# MEC1727N_B0_SZ register map
Vendor: Microchip Technology; Series: MEC172x; File version: 0
CPU: CM4 r1p0, little endian, MPU, FPU, 3 interrupt priority bits, 172 interrupts
Registers are 32-bit, read-write, reset 0x0 unless marked. A register's access mark holds for its fields unless they carry their own. Offsets are from the block's base; [hi:lo] are bit positions; {n}, {i} and the like mark numbered series; 'fields as' and 'values as' point back to an identical list.

## ESPI_IO — The ESPI is used by the system host to configure the chip and communicate with the logical devices implemented in the design.
Base 0x400F3400
0x00 IND 8-bit — The INDEX register, which is part of the Configuration Port, is used as a pointer to a Configuration Register Address.
0x01 DAT_REG 8-bit — The DATA register, which is part of the Configuration Port, is used to read or write data to the register currently being selected by the INDEX Register.
0x100 PC_LC_ADDR_LSW ro — Peripheral Channel Last Cycle Register (DWord 0)
  [31:0] LADR — This field records bits[31:0] of the 64 bit address of the most recent eSPI transaction.
0x104 PC_LC_ADDR_MSW ro — Peripheral Channel Last Cycle Register (DWord 1)
  [31:0] MADR — This field records bits[63:32] of the 64 bit address of the most recent eSPI transaction.
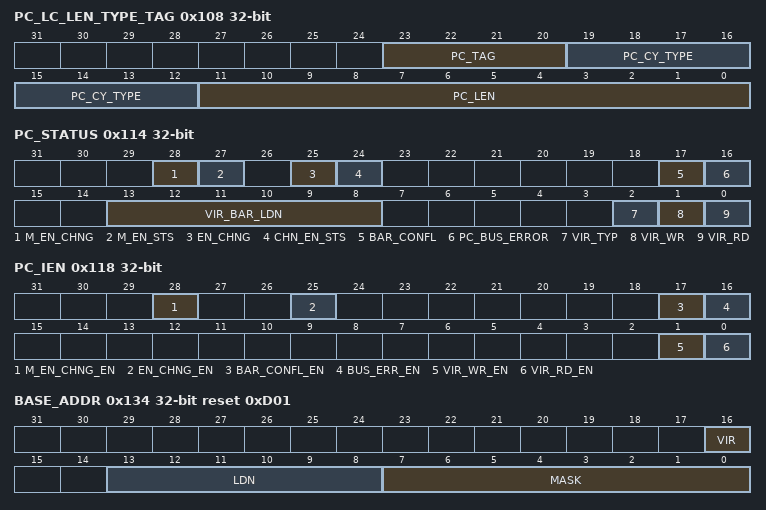
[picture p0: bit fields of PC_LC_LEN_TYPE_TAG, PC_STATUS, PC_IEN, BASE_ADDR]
0x108 PC_LC_LEN_TYPE_TAG ro — Peripheral Channel Last Cycle Register (DWord 2)
  [23:20] PC_TAG — This field records the tag of the most recent eSPI transaction.
  [19:12] PC_CY_TYPE — This field records the cycle type of the most recent eSPI transaction.
  [11:0] PC_LEN — This field records the length of the most recent eSPI transaction.
0x10C PC_ERR_ADDR_LSW ro — Peripheral Channel Error Address Register (DWord 0)
  [31:0] LSDW — This field records bits[31:0] of the 64 bit address of the most recent eSPI transaction that incurred an error.
0x110 PC_ERR_ADDR_MSW ro — Peripheral Channel Error Address Register (DWord 1)
  [31:0] MSDW — This field records bits[63:32] of the 64 bit address of the most recent eSPI transaction that incurred an error.
0x114 PC_STATUS — Peripheral Channel Status Register
  [28] M_EN_CHNG — This bit is set to '1' whenever the field PC_MASTERING_ENABLE_STATUS in this register changes. Once set, it remains set until cleared by being written with a 1 (R/WC)
  [27] M_EN_STS — This bit is 1 if three bits in the Peripheral Channel Capabilities and Configurations register, Peripheral Channel Mastering Enable, Peripheral Channel Ready and Peripheral Channel Enable, are all 1, and 0 otherwise.
  [25] EN_CHNG — This bit is set to '1' whenever the field PC_CHANNEL_ENABLE_STATUS in this register changes. Once set, it remains set until cleared by being written with a 1. (R/WC)
  [24] CHN_EN_STS — This bit reflects the Host writable configuration field.
  [17] BAR_CONFL — This bit is set to '1' whenever a BAR conflict occurs on an eSPI address. A BAR conflict occurs when more than one BAR matches the address of an eSPI transaction. Once set, it remains set until cleared by being written with a 1. (R/WC)
  [16] PC_BUS_ERROR — This bit is set to '1' whenever an eSPI access causes an internal bus error. Once set, it remains set until cleared by being written with a 1. (R/WC)
  [13:8] VIR_BAR_LDN — This field returns the Logical Device Number of the device targeted by the most recent virtual transaction.
  [2] VIR_TYP — This bit returns the type of Virtualized eSPI transaction that is 1=Peripheral Channel Memory Address access 0=Peripheral Channel I/O Address access.
  [1] VIR_WR — This bit is set whenever a eSPI write transaction targeting a Logical Device with an I/O BAR or a Memory BAR in which the VIRTUALIZED bit is set. (R/WC)
  [0] VIR_RD — This bit is set whenever a eSPI read transaction targeting a Logical Device with an I/O BAR or a Memory BAR in which the VIRTUALIZED bit is set. (R/WC)
0x118 PC_IEN — Peripheral Channel Interrupt Enable Register
  [28] M_EN_CHNG_EN — When this bit is '1' an interrupt is generated when the bit PC_MASTERING_ENABLE_CHANGE in the Peripheral Channel Status Register is 1. When this bit is '0', the status bit will not generate an interrupt.
  [25] EN_CHNG_EN — When this bit is '1' an interrupt is generated when the bit PC_ENABLE_CHANGE in the Peripheral Channel Status Register is 1. When this bit is '0', the status bit will not generate an interrupt.
  [17] BAR_CONFL_EN — When this bit is '1' an interrupt is generated when the bit BAR_CONFLICT in the Peripheral Channel Status Register is 1. When this bit is '0', the status bit will not generate an interrupt.
  [16] BUS_ERR_EN — When this bit is '1' an interrupt is generated when the bit PC_BUS_ERROR in the Peripheral Channel Status Register is 1. When this bit is '0', the status bit will not generate an interrupt.
  [1] VIR_WR_EN — When this bit is '1' an interrupt is generated when the bit PC_VIRTUAL_WRITE in the Peripheral Channel Status Register is 1. When this bit is '0', the status bit will not generate an interrupt.
  [0] VIR_RD_EN — When this bit is '1' an interrupt is generated when the bit PC_VIRTUAL_READ in the Peripheral Channel Status Register is 1. When this bit is '0', the status bit will not generate an interrupt.
0x120 IOBAR_INH_LSW — BAR Inhibit Register (DWord 0)
  [31:0] LSDW — When bit Di of BAR_Inhibit is 1, the BAR for Logical Device i is disabled and its addresses will not be claimed on the eSPI bus, independent of the value of the Valid bit in the BAR. The BAR Inhibit function applies to both I/O transactions and Memory transactions.
0x124 IOBAR_INH_MSW — BAR Inhibit Register (DWord 1)
  [31:0] MSDW — When bit Di of BAR_Inhibit is 1, the BAR for Logical Device i is disabled and its addresses will not be claimed on the eSPI bus, independent of the value of the Valid bit in the BAR. The BAR Inhibit function applies to both I/O transactions and Memory transactions.
0x128 IOBAR_INIT reset 0x2E — eSPI BAR Init Register
  [15:0] INIT — This field is loaded into the Base Address Register register for Logical Device Ch (eSPI, I/O Configuration Port) on RESET_SIO.
0x12C EC_CTRL_IRQ — EC IRQ Register
  [0] IRQ — This bit can be used as a firmware-controlled interrupt source for the EC. When the EC entry in the IRQ Assignment Table is set to a valid IRQ number, changes in this bit will be transmitted to the Host over a Virtual Wire IRQ channel.
0x134 BASE_ADDR reset 0xD01 — eSPI I/O Base Address Register
  [16] VIR — 1=Peripheral Channel I/O for this device is virtualized, and reads and writes are handled in firmware 0=All Peripheral Channel I/O Reads and Writes for this device are completed by hardware.
  [13:8] LDN — These 6 bits are used to specify a logical device number within a bus. This field is multiplied by 400h to provide the address within the peripheral bus address. Logical Device Numbers that do not corresponding to logical devices that are present on the device are invalid.
  [7:0] MASK — These 8 bits are used to mask off address bits in the address match between an eSPI I/O address and the Host Address field of the BARs. A block of up to 256 8-bit registers can be assigned to one base address.
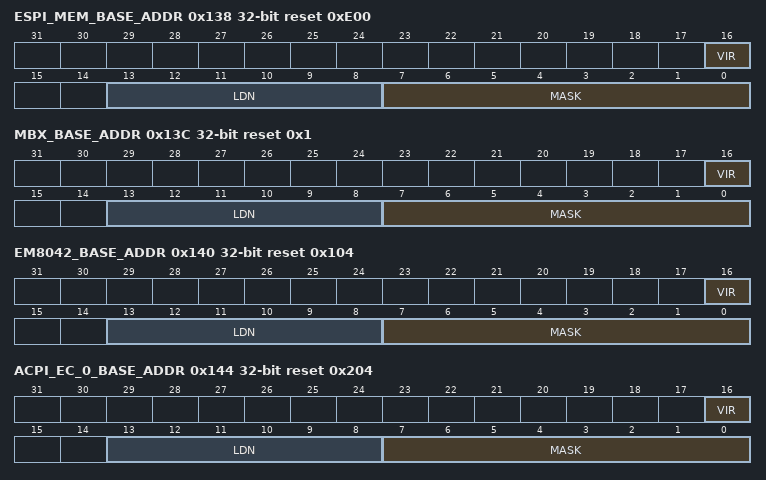
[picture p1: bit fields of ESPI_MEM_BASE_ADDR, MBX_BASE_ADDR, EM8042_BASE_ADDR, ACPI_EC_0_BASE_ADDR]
0x138 ESPI_MEM_BASE_ADDR reset 0xE00 — eSPI Memory Base Address Register
  fields as BASE_ADDR
0x13C MBX_BASE_ADDR reset 0x1 — Mailbox BAR Register
  fields as BASE_ADDR
0x140 EM8042_BASE_ADDR reset 0x104 — 8042 Emulated Keyboard Controller BAR Register
  fields as BASE_ADDR
0x144 ACPI_EC_0_BASE_ADDR reset 0x204 — ACPI EC Channel 0 Register
  fields as BASE_ADDR
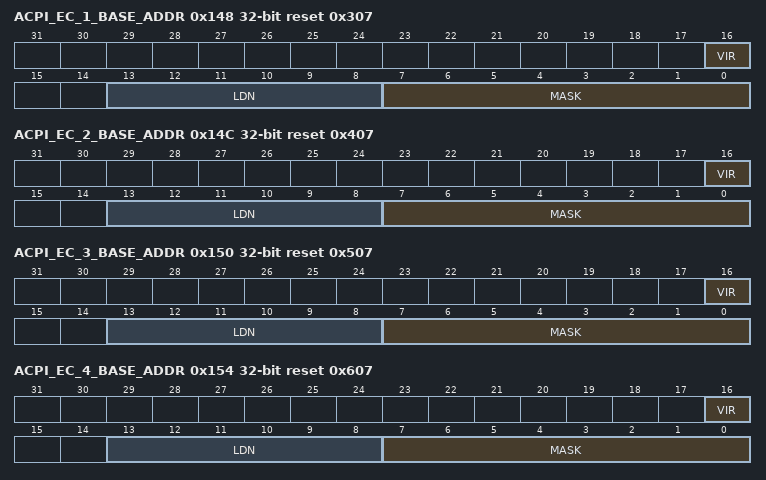
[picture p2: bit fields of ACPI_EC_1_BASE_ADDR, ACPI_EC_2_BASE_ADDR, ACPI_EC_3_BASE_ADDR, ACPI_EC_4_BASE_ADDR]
0x148 ACPI_EC_1_BASE_ADDR reset 0x307 — ACPI EC Channel 1 BAR Register
  fields as BASE_ADDR
0x14C ACPI_EC_2_BASE_ADDR reset 0x407 — ACPI EC Channel 2 BAR Register
  fields as BASE_ADDR
0x150 ACPI_EC_3_BASE_ADDR reset 0x507 — ACPI EC Channel 3 BAR Register
  fields as BASE_ADDR
0x154 ACPI_EC_4_BASE_ADDR reset 0x607 — ACPI EC Channel 4 BAR Register
  fields as BASE_ADDR
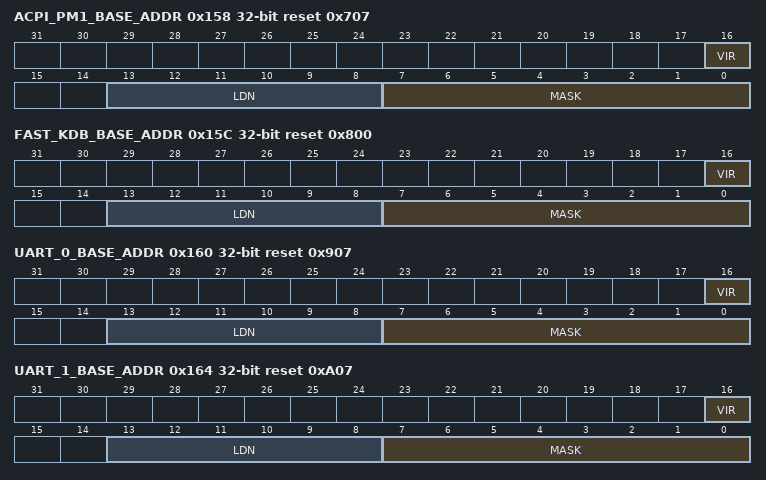
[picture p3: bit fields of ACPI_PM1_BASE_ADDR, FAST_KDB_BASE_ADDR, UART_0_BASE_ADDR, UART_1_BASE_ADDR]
0x158 ACPI_PM1_BASE_ADDR reset 0x707 — I/O Base Address Register
  fields as BASE_ADDR
0x15C FAST_KDB_BASE_ADDR reset 0x800 — Legacy (Fast Keyboard) BAR Register
  fields as BASE_ADDR
0x160 UART_0_BASE_ADDR reset 0x907 — UART 0 BAR Register
  fields as BASE_ADDR
0x164 UART_1_BASE_ADDR reset 0xA07 — UART 1 BAR Register
  fields as BASE_ADDR
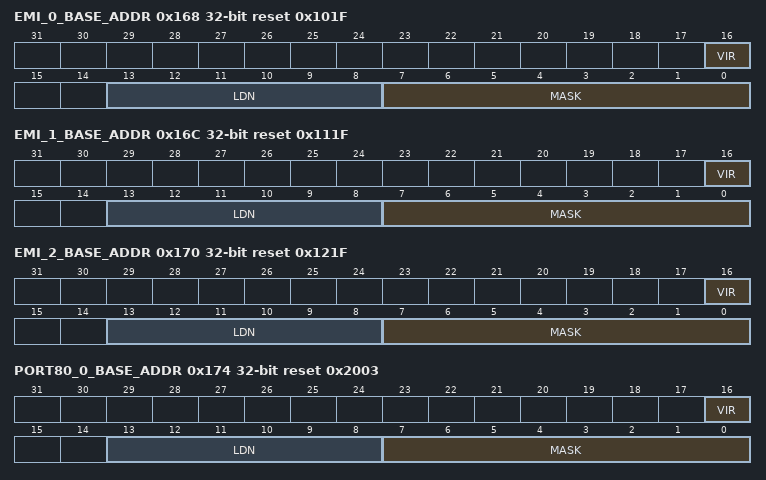
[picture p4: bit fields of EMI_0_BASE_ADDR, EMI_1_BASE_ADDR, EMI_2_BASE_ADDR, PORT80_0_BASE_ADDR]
0x168 EMI_0_BASE_ADDR reset 0x101F — Embedded Memory Interface (EMI) 0 BAR Register
  fields as BASE_ADDR
0x16C EMI_1_BASE_ADDR reset 0x111F — Embedded Memory Interface (EMI) 1 BAR Register
  fields as BASE_ADDR
0x170 EMI_2_BASE_ADDR reset 0x121F — Embedded Memory Interface (EMI) 2 BAR Register
  fields as BASE_ADDR
0x174 PORT80_0_BASE_ADDR reset 0x2003 — BIOS Debug Port (Port 80) 0 BAR Register
  fields as BASE_ADDR
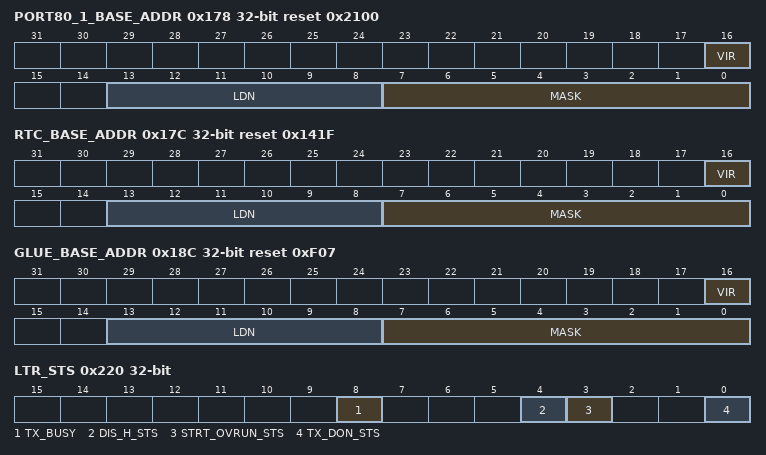
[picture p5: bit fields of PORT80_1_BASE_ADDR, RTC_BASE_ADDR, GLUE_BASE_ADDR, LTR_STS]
0x178 PORT80_1_BASE_ADDR reset 0x2100 — BIOS Debug Port (Port 80) 1 BAR Register
  fields as BASE_ADDR
0x17C RTC_BASE_ADDR reset 0x141F — RTC Base Address Register
  fields as BASE_ADDR
0x18C GLUE_BASE_ADDR reset 0xF07 — GLUE Base Address Register
  fields as BASE_ADDR
0x220 LTR_STS — LTR Peripheral Status Register
  [8] TX_BUSY — This bit is set to '1' when firmware writes '1' to the LTR_START (ltr_initiate) bit in the LTR Peripheral Control Register. It is cleared by hardware when the transfer is sufficiently complete so that another packet can be transmitted. If the LTR_START bit is written to '1' while this bit is also '1', then START_OVERRUN_STATUS in this register will be set to '1' and the transfer will terminate immediately.
  [4] DIS_H_STS — A '1' in this bit indicates that the last requested Transmit operation was aborted because Bus Mastering has been disabled by the Host. Bus Mastering is disabled whenever the Peripheral Channel Mastering Enable bit in that register is '0', or the Peripheral Channel Enable bit is '0'.
  [3] STRT_OVRUN_STS — A Start was attempted while the TRANSMIT_BUSY bit in this register was '1'. Any Transmit in progress is immediately terminated. (R/WC)
  [0] TX_DON_STS — This bit is set to '1' whenever a Transmit operation terminates (the TRANSMIT_DONE bit in this register goes from 1 to 0). (R/WC)
0x224 LTR_EN — LTR Peripheral Enable Register
  [0] TX_DONE_IEN — When this bit is '1' an interrupt is generated when the bit TRANSMIT_DONE_STATUS in the LTR Peripheral Status Register is 1. When this bit is '0', the status bit will not generate an interrupt.
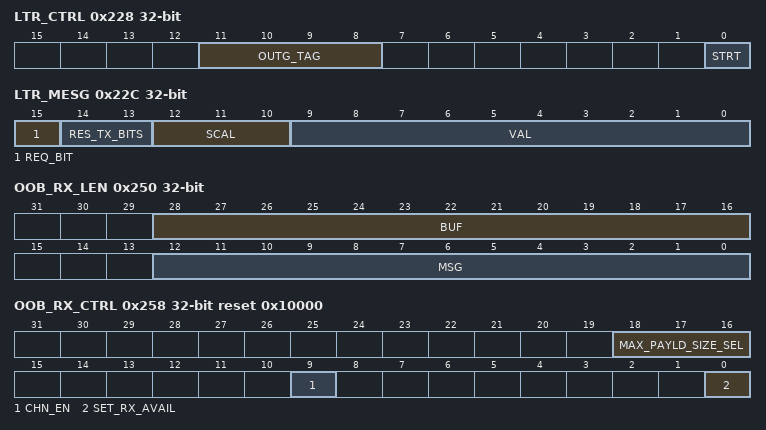
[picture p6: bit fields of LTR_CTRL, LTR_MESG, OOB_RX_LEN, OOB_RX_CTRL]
0x228 LTR_CTRL — LTR Peripheral Control Register
  [11:8] OUTG_TAG — This 4-bit value will be inserted as the TAG number in the next transmitted LTR packet. According to current understanding of Intel specs, this field should be kept zero by firmware.
  [0] STRT — Writing '1' to this bit triggers the transmission of an LTR packet defined by the LTR Peripheral Message register. Writing '0' to this bit has no effect. The transmission will be inhibited if the Peripheral channel is not Ready, as defined in the eSPI Peripheral Channel Ready Register.
0x22C LTR_MESG — LTR Peripheral Message Register
  [15] REQ_BIT — 1 = Maximum latency tolerated is defined by the Scale and Length fields of this register. 0 = No Requirement. Infinite latency tolerated. (Default).
  [14:13] RES_TX_BITS — These bits are Read/Write, but are undefined in the 16-bit LTR message format. These bits are transmitted, but according to current specs they must always be kept as zeros when writing this register.
  [12:10] SCAL — This field declares the time unit expressed by each count of the Value field of this register.
  [9:0] VAL — This field declares a time, in units expressed by the Scale field. Zero in both this field and the Scale field (zero time) demands best possible effort (minimal latency) by the chipset.
0x240 OOB_RX_ADDR_LSW — OOB Channel Receive Address Register
  [31:2] RX_BUF — This field must be initialized to contain the Base Address for accepting the next OOB packet.
0x248 OOB_TX_ADDR_LSW — OOB Channel Transmit Address Register
  [31:2] TX_BUF — Before starting an OOB Transmit, this field must be initialized to contain the Base Address of the buffer in SRAM. The contents of the transmit buffer should not be modified while TRANSMIT_BUSY is asserted.
0x250 OOB_RX_LEN — OOB Channel Receive Length Register
  [28:16] BUF — Before setting the Receive Enable bit to allow incoming traffic to the Receive Buffer area, this 13-bit field must be initialized to contain the length in bytes of the receiving buffer in SRAM. This limits the number of bytes that can be received into SRAM. Any additional incoming bytes must be discarded by hardware, posting the Data Overrun error flag. Practically, the maximum value that can be placed in this field is the configured Max Packet Length. This limit, or anything higher, is legal, but will effectively disable the limit check.
  [12:0] MSG — This 13-bit read-only field reports how many bytes were received into SRAM in the last packet. This is necessary, independent of any 'byte count' in the packet itself to distinguish between an SMBus packet with or without a PEC byte.
0x254 OOB_TX_LEN — OOB Channel Transmit Length Register
  [12:0] MSG — This 13-bit field declares how many bytes are to be transmitted from the Tramsit Buffer memory. A value of zero, or a value greater than the defined Max Packet Size (73 decimal, or 4Dh, by default) is illegal, and will trigger Bad Request handling.
0x258 OOB_RX_CTRL reset 0x10000 — OOB Channel Receive Control Register
  [18:16] MAX_PAYLD_SIZE_SEL — This allows firmware to read the correspondingly-named field in the eSPI Configuration register. The 001b default code selects 64-byte mode, which is actually a 73-byte max payload size for eSPI (64 bytes plus MCTP wrapper bytes).
  [9] CHN_EN — This allows firmware to read the OOB Message Channel Enabled field in the eSPI Configuration register. The Master sets the bit to '1' to enable the OOB channel.
  [0] SET_RX_AVAIL — Firmware sets this bit to '1' to indicate that an SRAM buffer is available to receive the next Down OOB packet. This forces the bit RECEIVE_ENABLE bit in the OOB Channel Receive Status Register register to be set to '1'. The OOB Channel Receive Address Register and OOB Channel Receive Length Register must have already been initialized before setting this bit.
0x25C OOB_RX_IEN — OOB Channel Receive Interrupt Enable Register
  [0] RX_IEN — When this bit is '1' an interrupt is generated when the bit RECEIVE_DONE_STATUS in the OOB Channel Receive Status Register is 1. When this bit is '0', the status bit will not generate an interrupt.
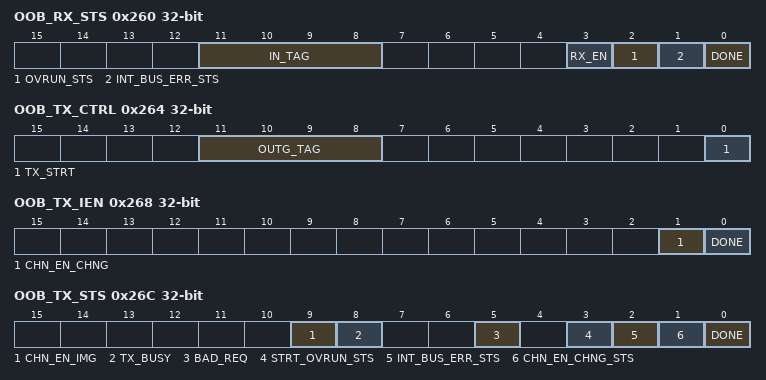
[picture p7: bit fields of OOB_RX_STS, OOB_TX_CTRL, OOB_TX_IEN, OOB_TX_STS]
0x260 OOB_RX_STS — OOB Channel Receive Status Register
  [11:8] IN_TAG — This field holds the 4-bit TAG in the last message received from the Master.
  [3] RX_EN — This bit is set to '1' when firmware sets the bit SET_RECEIVE_AVAILABLE in the OOB Channel Receive Control Register to '1', to indicate that an SRAM buffer is available to receive the next Down OOB packet. The OOB Channel Receive Address Register and OOB Channel Receive Length Register must have already been initialized before setting this bit. This bit is cleared by hardware when the next packet is received. The RECEIVE_DONE_STATUS bit is set to '1' after this bit is cleared. A '0' in this bit does not necessarily present 'Not Free' status to the eSPI Master. As long as FIFO space is available for a complete OOB packet, the packet can be input and held in the FIFO until this bit is again set by firmware.
  [2] OVRUN_STS — This bit is set to '1' whenever an incoming packet is truncated because it was longer than the RECEIVE_BUFFER_LENGTH field. Incoming extra bytes are discarded when this error is triggered, but the buffer receives the data up to its limit, for debugging purposes. (R/WC)
  [1] INT_BUS_ERR_STS — This bit is set to '1' whenever the channel tries to write an incoming byte into an invalid area of the internal addressing space. This could happen if the OOB Channel Receive Address Register was set to something invalid by firmware. If this error occurs mid-packet(crossing a boundary into an invalid space), then the remaining data is discarded. (R/WC).
  [0] DONE — This bit is set to '1' whenever the RECEIVE_ENABLE bit in this register is cleared to '0' by hardware when an incoming packet is completely transferred to SRAM. This bit is also set whenever either OVERRUN_STATUS or INTERNAL_BUS_ERROR_STATUS in this register are set to '1'. (R/WC).
0x264 OOB_TX_CTRL — OOB Channel Transmit Control Register
  [11:8] OUTG_TAG — This 4-bit value will be inserted as the TAG number in the next transmitted OOB packet. This field must be 0.
  [0] TX_STRT — A write of '1' to this bit starts the transmission of an OOB packet defined by the OOB Channel Transmit Address Register and OOB Channel Transmit Length Register registers. A write of '0' has no effect. The transmission will be inhibited if the OOB channel is not Ready, as defined in the eSPI OOB Channel Ready Register.
0x268 OOB_TX_IEN — OOB Channel Transmit Interrupt Enable Register
  [1] CHN_EN_CHNG — When this bit is '1' an interrupt is generated when the bit CHANNEL_ENABLE_CHANGE_STATUS in the OOB Channel Transmit Status Register is 1. When this bit is '0', the status bit will not generate an interrupt.
  [0] DONE — When this bit is '1' an interrupt is generated when the bit TRANSMIT_DONE_STATUS in the OOB Channel Transmit Status Register is 1. When this bit is '0', the status bit will not generate an interrupt.
0x26C OOB_TX_STS — OOB Channel Transmit Status Register
  [9] CHN_EN_IMG — This bit is an image of the OOB Channel Enabled bit in the OOB Channel Receive Control Register register. It is provided here so that it can be seen with the CHANNEL_ENABLE_CHANGE_STATUS Interrupt Status bit for efficiency.
  [8] TX_BUSY — This bit is set to '1' when firmware writes '1' to the TRANSMIT_START bit. It is cleared by hardware when the transfer is complete. If the TRANSMIT_START bit is written '1' while this bit is also '1', then this will set the START_OVERRUN_STATUS bit to '1' and terminate the transfer attempt immediately (Transmit Done).
  [5] BAD_REQ — This bit is intended for any situation where a firmware request cannot be started because it expresses something impossible. This bit will be set for a request to Transmit 0 bytes or if a Transmit length is more than the selected Max Payload Length. This condition brings the state machine to the Done state, as if something had actually finished, with everything including the Done interrupt triggered. (R/WC)
  [3] STRT_OVRUN_STS — This error flag indicates a Start was attempted while the channel was Busy. Any Transmit in progress is immediately halted. (R/WC)
  [2] INT_BUS_ERR_STS — This error flag indicates an internal bus violation occurred in trying to transmit. (R/WC)
  [1] CHN_EN_CHNG_STS — This bit is set to '1' whenever the eSPI Master changes the state of the OOB Message Channel Enable bit in the OOB Channel Capabilities and Configurations Master register. (R/WC).
  [0] DONE — This bit is set to '1' whenever a Transmit operation terminates (TRANSMIT_BUSY in this register goes from '1' to '0'). (R/WC)
0x280 FC_FLASH_ADDR_LSW — Flash Access Channel Flash Address Register
  [31:0] FLSW — Before starting a Flash access, this field must be initialized to contain the value used by eSPI for addressing the Flash contents.
0x288 FC_BUF_ADDR_LSW — Flash Access Channel Buffer Address Register
  [31:0] BLSW — Before starting a Flash access, this field must be initialized with the address of the data buffer in the EC's memory space.
0x290 FC_XFR_LEN — Flash Access Channel Transfer Length Register
  [31:0] TLEN — Before starting a Flash access, this field must be initialized with the total number of bytes to be transferred in the requested transaction sequence. If the Master attempts to transfer more bytes than this in Read Completions, the transfer is faulted and the DATA_OVERRUN bit in the Flash Access Channel Status Register register is asserted.
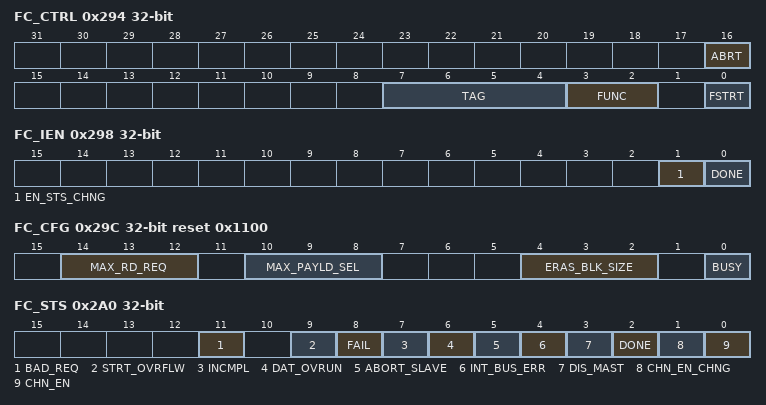
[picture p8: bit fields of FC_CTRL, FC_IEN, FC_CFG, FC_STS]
0x294 FC_CTRL — Flash Access Channel Control Register
  [16] ABRT — By writing '1' to this bit while Busy==1, the transaction sequence last triggered by the Start bit is terminated, and the Busy bit is cleared, at the next protocol-compliant opportunity. The clearing of the Busy bit will set the DONE status bit and the ABORTED_BY_SLAVE status bit is set to '1' to acknowledge this specific action as the cause. The action of writing '1' to this bit is ignored while Busy==0. This bit reads as '0' always.
  [7:4] TAG — This field should always be written to zero, which is the only expected Tag value for Flash Access traffic. It provides the 4-bit TAG value in the eSPI Transaction Header sent by the EC. Completion traffic from the Master is required to match this field also.
  [3:2] FUNC — This bit selects the requested Flash function as follows: 11=Erase Flash Range=Larger of two ranges, if a choice exists 10=Erase Flash Range=Smaller of two ranges, if a choice exists 01=Write to Flash 00=Read from Flash.
  [0] FSTRT — A write of '1' to this bit starts the transmission and sets the Busy status bit. A write of '0' has no effect. The transmission will be inhibited if the OOB channel is not Ready, as defined in the eSPI Flash Channel Ready Register.
0x298 FC_IEN — Flash Access Channel Interrupt Enable Register
  [1] EN_STS_CHNG — When this bit is '1' an interrupt is generated when the bit CHANNEL_ENABLE_CHANGE_STATUS in the Flash Access Channel Status Register is 1. When this bit is '0', the status bit will not generate an interrupt.
  [0] DONE — When this bit is '1' an interrupt is generated when the bit DONE in the Flash Access Channel Status Register is 1. When this bit is '0', the status bit will not generate an interrupt.
0x29C FC_CFG ro reset 0x1100 — Flash Access Channel Configuration Register
  [14:12] MAX_RD_REQ — This comes read-only from the eSPI Configuration register, set by the Master to declare the maximum number of bytes that can be requested by the EC in a single Flash Read request packet. 111b = 4K bytes 110b = 2K bytes 101b = 1K bytes 100b = 512 bytes 011b = 256 bytes 010b = 128 bytes 001b = 64 bytes 000b = Reserved.
  [10:8] MAX_PAYLD_SEL — This is a read-only image of the equivalent field of the eSPI Configuration register, set by the Master to declare the maximum number of bytes that can be used in a single Flash payload, in either direction. It will never be set greater than the value provided by the EC in the FLASH_MAXIMUM_PAYLOAD_SIZE_SUPPORTED field in the eSPI Flash Channel Capabilities Register. 100b -- 111b = Reserved 011b = 256 bytes 010b = 128 bytes 001b = 64 bytes 000b = Reserved.
  [4:2] ERAS_BLK_SIZE — This is a read-only image of the equivalent field of the eSPI Configuration register. This field is set by the Master to define what the Erase block size is for the Flash being used, and whether there is a choice available to firmware. 111b = Reserved 110b = Reserved 101b = 256K 100b = 128K 010b = 64K 011b = Both 4K and 64K allowed (see FUNCTION field) 001b = 4K 000b = Reserved.
  [0] BUSY — This bit is set to '1' when a '1' is written to the FLASH_START bit, and cleared either by hardware completion of the requested operation or by firmware writing '1' to the ABORT_ACCESS bit. 1=The Channel is busy. 0=The Channel is not busy.
0x2A0 FC_STS — Flash Access Channel Status Register
  [11] BAD_REQ — This bit is set to '1' when a firmware Flash Access request is invalid. For example, this bit is set for a request to Read or Write 0 bytes. This bit is cleared by writing '1'. (R/WC)
  [9] STRT_OVRFLW — This bit is set if a command (initiated by setting the Start bit) has been ignored because the Busy bit was already on. The transfer in progress is also brought to the Done state at the next opportunity allowed by the eSPI protocol, as if the Abort bit had been set by the firmware, so that this bit will be present at a Done interrupt. This bit is cleared by writing '1'. (R/WC) This flag represents a serious mis-communication between the firmware and hardware, and should be handled cautiously as a special case by firmware. 1=Start Overflow. Firmware has attempted to trigger a transaction sequence before allowing the previous sequence to finish and without using the Abort bit to terminate it first 0=No Start Overflow detected.
  [8] FAIL — This bit is set to '1' by an explicit UNSUCCESSFUL COMPLETION response from the eSPI Master, which also terminates the transaction sequence. This may occur if an invalid or illegal section of Flash memory is accessed, and only at Runtime (post-boot). This bit is cleared by writing '1'. (R/WC) 1=The eSPI Master indicated unsuccessful completion. 0=The eSPI Master indicated successful completion.
  [7] INCMPL — This bit is set to '1' by a SUCCESSFUL COMPLETION Read response from the eSPI Master, indicating a Final Completion, but with too few bytes provided for the Transaction step that was issued by the eSPI Slave. It is cleared by writing '1'. This bit is cleared by writing '1'. (R/WC) 1=The eSPI Master finished with too little data. 0=The eSPI Master finished with at least enough data.
  [6] DAT_OVRUN — This bit is set to '1' by a SUCCESSFUL COMPLETION response by the eSPI Master to a Read sequence, but either without indicating Final Completion when the requested byte count is reached or with too many bytes provided while indicating Final Completion. It is cleared by writing '1'. (R/WC) 1=The eSPI Master finished with too much data. 0=The eSPI Master finished without too much data.
  [5] ABORT_SLAVE — This bit is set to '1' if the Abort bit is set to '1' by firmware while the Busy bit is '1', thereby clearing Busy status. It is cleared by writing '1'. (R/WC) 1=The command finished because of the Abort bit. 0=The command finished without an Abort bit activation.
  [4] INT_BUS_ERR — This bit is set to '1' if the internal bus master associated with the Flash Access Channel encounters a Bus Fault condition. It is cleared by writing '1'. (R/WC) 1=Bus Error detected. 0=The command finished without a Bus Error.
  [3] DIS_MAST — This bit is set to '1' if the Flash Channel is disabled by the Master while the Busy bit is '1'. It is cleared by writing '1'. (R/WC) 1=The command finished because the Enable bit became 0. 0=The command finished without a change in the Enable bit.
  [2] DONE — 1=Channel is done=Busy bit has been cleared since this bit was last cleared. It is cleared by writing '1'. (R/WC) 0=Channel is not done=Busy bit has not been cleared since this bit was last cleared.
  [1] CHN_EN_CHNG — 0=Flash Access Enable bit in eSPI Configuration space has not been changed since this bit was last cleared. 1=Flash Access Enable bit in eSPI Configuration space has been changed since this bit was last cleared. The current state of the Flash Access Enable bit can be seen as the read-only bit CHANNEL_ENABLE_STATUS in this register. This bit is cleared by writing '1'. (R/WC)
  [0] CHN_EN — This bit is a Read-only image of the bit Flash Access Channel Enable in the eSPI Configuration space. Rising or falling edges of this bit will set the CHANNEL_ENABLE_CHANGE_STATUS bit to 1, and may be used to trigger interrupts. A falling edge on this bit, while Busy==1, will also clear the Busy bit and set the DONE bit, with DISABLED_BY_MASTER status. 1=Flash Access Channel Enable bit = 1. 0=Flash Access Channel Enable bit = 0.
0x2B0 VW_EN_STS 8-bit ro — Virtual Wire Status Register
  [0] CHN_EN_STS — This bit is a Read-only image of the bit Virtual Wire Channel Enable in the eSPI Configuration space. 1=Virtual Wire Channel Enable bit = 1; 0=Virtual Wire Channel Enable bit = 0.
0x2E0 CAP_ID 8-bit reset 0x1 — eSPI Capabilities ID Register
  [7:0] ESP_DEVID — The default value should not be changed.
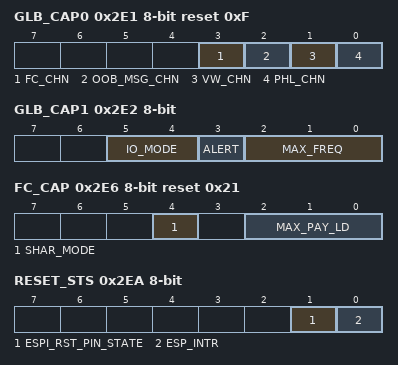
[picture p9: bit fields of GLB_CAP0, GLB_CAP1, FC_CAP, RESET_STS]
0x2E1 GLB_CAP0 8-bit reset 0xF — eSPI Capabilities Global Capabilities 0 Register
  [3] FC_CHN — 1=Flash Access Channel is supported by the slave; 0=Flash Access Channel not supported by the slave.
  [2] OOB_MSG_CHN — 1=OOB Message Channel is supported by the slave; 0=OOB Message Channel not supported by the slave.
  [1] VW_CHN — 1=Virtual Wire Channel is supported by the slave; 0=Virtual Wire Channel Channel not supported by the slave.
  [0] PHL_CHN — 1=Peripheral Channel is supported by the slave; 0=Peripheral Channel not supported by the slave.
0x2E2 GLB_CAP1 8-bit — eSPI Capabilities Global Capabilities 1 Register
  [5:4] IO_MODE — This field identifies the I/O modes supported by the slave. It corresponds to the field I/O Mode Support, bits [25:24] of the eSPI General Capabilities and Configurations register. 11b=Single, Dual and Quad I/O 10b=Single and Quad I/O 01b=Single and Dual I/O 00b=Single I/O (default).
  [3] ALERT — This field is a read-only copy of the ALERT Mode field, bit 28 of the Config Offset 8h=General Capabilities and Configurations Register.
  [2:0] MAX_FREQ — This field identifies the maximum frequency of operation supported by the slave. It corresponds to the field Maximum Frequency Supported, bits [18:16] of the eSPI General Capabilities and Configurations register. 111b - 101b=Reserved 100b=66 MHz 011b=50 MHz 010b=33 MHz 001b=25 MHz 000b=20 MHz (default).
0x2E3 PC_CAP 8-bit reset 0x1 — eSPI Peripheral Channel Capabilities Register
  [2:0] MAX_PAYLD_SIZE — This field identifies the maximum payload size supported by the slave. It corresponds to the field Peripheral Channel Maximum Payload Size Supported, bits [6:4] of the Peripheral Channel Capabilities and Configurations Register. 111b - 100b=Reserved 011b=256 bytes address aligned max payload size 010b=128 bytes address aligned max payload size 001b=64 bytes address aligned max payload size 000b=Reserved.
0x2E4 VW_CAP 8-bit reset 0x3F — eSPI Virtual Wire Channel Capabilities Register
  [5:0] MAX_CNT — This field identifies the maximum Virtual Wire Count supported by the slave. It corresponds to the field Maximum Virtual Wire Count Supported, bits [13:8] of the Virtual Wire Channel Capabilities and Configurations Register. This field must be set to a number greater than or equal to 7h.
0x2E5 OOB_CAP 8-bit reset 0x1 — eSPI OOB Channel Capabilities Register
  [2:0] MAX_PAYLD_SIZ — This field identifies the maximum payload size supported by the slave. It corresponds to the field OOB Message Channel Maximum Payload Size Supported, bits [6:4] of the OOB Channel Capabilities and Configurations Register. 111b - 100b=Reserved 011b=265 bytes address max payload size 010b=137 bytes address max payload size 001b=73 bytes address max payload size 000b=Reserved.
0x2E6 FC_CAP 8-bit reset 0x21 — eSPI Flash Channel Capabilities Register
  [4] SHAR_MODE — This field identifies the flash sharing scheme supported by the slave. It corresponds to the field Flash Sharing Mode, bit [11] of the Flash Channel Capabilities and Configurations Register. 1=Slave attached flash sharing 0=Master attached flash sharing
  [2:0] MAX_PAY_LD — This field identifies the maximum payload size supported by the slave. It corresponds to the field Flash Access Channel Maximum Payload Size Supported, bits [7:0] of the Flash Channel Capabilities and Configurations Register. 111b - 100b=Reserved 011b=256 bytes address aligned max payload size 010b=128 bytes address aligned max payload size 001b=64 bytes address aligned max payload size 000b=Reserved.
0x2E7 PC_READY 8-bit — eSPI Peripheral Channel Ready Register
  [0] PHL_CHN_RDY — Firmware sets this bit to '1' to inform the Master than the Peripheral channel is ready for transactions. It corresponds to the field Peripheral Channel Ready, bit 1 of the Config Offset 10h=Peripheral Channel Capabilities and Configurations Register. It is forced to '0' while the Peripheral Channel Enabled bit in the Capabilities and Configurations register is 0. Once set to '1' it cannot be set to '0' by firmware. It is only set to '0' by a reset, or when the Master changes the Enabled bit to '0'. While this bit is '0' all Bus Master and LTR transactions initiated by the Slave are inhibited.
0x2E8 OOB_READY 8-bit — eSPI OOB Channel Ready Register
  [0] CHN — Firmware sets this bit to '1' to inform the Master that the OOB channel is ready for transactions. It corresponds to the field OOB Message Channel Ready, bit 1 of Config Offset 30h=OOB ChannelCapabilities and Configurations Register. It is forced to '0' while the OOB Message Channel Enabled bit in the Capabilities and Configurations register is 0. Once set to '1' it cannot be set to '0' by firmware. It is only set to '0' by a reset, or when the Master changes the Enabled bit to '0'. While this bit is '0' all OOB up transactions initiated by the Slave are inhibited.
0x2E9 FC_READY 8-bit — eSPI Flash Channel Ready Register
  [0] CHN — Firmware sets this bit to '1' to inform the Master that the Flash channel is ready for transactions. It corresponds to the field Flash Channel Ready, bit 1 of Config Offset 40h=Flash Channel Capabilities and Configurations Register. It is forced to '0' while the Flash Channel Enabled bit in the Capabilities and Configurations register is 0. Once set to '1' it cannot be set to '0' by firmware. It is only set to '0'by a reset, or when the Master changes the Enabled bit to '0'. While this bit is '0' all Flash transactions initiated by the Slave are inhibited.
0x2EA RESET_STS 8-bit — eSPI Reset Interrupt Status Register
  [1] ESPI_RST_PIN_STATE — This field reflects the current state of the eSPI_RESET# pin.
  [0] ESP_INTR — This bit is set to '1' whenever the ESPI_RESET_PIN_STATE bit in this register changes state. It is cleared to '0' whenever it is written with a '1'. Writes of a '0' have no effect. (R/WC) This bit is the source for the eSPI_RESET Interrupt. The interrupt is asserted when both this bit and the ESPI_RESET_INTERRUPT_ENABLE bit in the eSPI Reset Interrupt Enable Register are '1'.
0x2EB RESET_IEN 8-bit — eSPI Reset Interrupt Enable Register
  [0] ESP_RIEN — 1=The RESET_ESPI Interrupt will be asserted when the ESPI_RESET_INTERRUPT_STATUS bit in the eSPI Reset Interrupt Status Register register is '1' 0=The RESET_ESPI Interrupt will not be asserted.
0x2EC PLTRST_SRC 8-bit — PLTRST Source Register
  [0] SRC — 1=The PLTRST reset signal is determined a signal external to the eSPI block. The PLTRST# virtual wire is ignored 0=The PLTRST reset signal is determined by the PLTRST# virtual wire.
0x2ED VW_READY 8-bit — eSPI Virtual Wire Channel Ready Register
  [0] CHN — Firmware sets this bit to '1' to inform the Master than the Virtual Wire channel is ready for transactions. It corresponds to the field Virtual Wire Channel Ready, bit 1 of the Config Offset 20h=Channel 1 Capabilities and Configurations Register. It is forced to '0' while the Virtual Wire Channel Enable bit in the Capabilities and Configurations register is 0. Once set to '1' it cannot be set to '0' by firmware. It is only set to '0' by a reset, or when the Master changes the Enabled bit to '0'. While this bit is '0' all Virtual Wire transactions initiated by the Slave are inhibited.
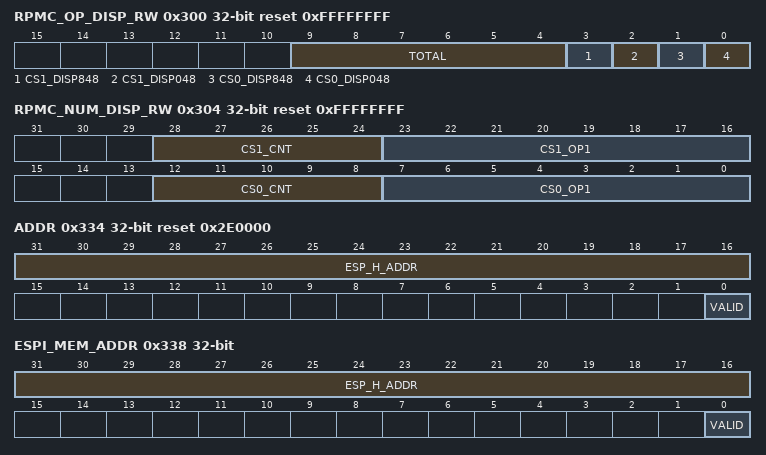
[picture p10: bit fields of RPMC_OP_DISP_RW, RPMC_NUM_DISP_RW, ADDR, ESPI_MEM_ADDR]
0x300 RPMC_OP_DISP_RW reset 0xFFFFFFFF — RPMC OP1 Opcode Display Configuration Register
  [9:4] TOTAL — RPMC Total
  [3] CS1_DISP848 — RPMC CS1 display 848 Sel
  [2] CS1_DISP048 — RPMC CS1 display 048 Sel
  [1] CS0_DISP848 — RPMC CS0 display 848 Sel
  [0] CS0_DISP048 — RPMC CS0 display 048 Sel
0x304 RPMC_NUM_DISP_RW reset 0xFFFFFFFF — RPMC OP1 Opcode Num Counter Register
  [28:24] CS1_CNT — RPMC CS1 Count
  [23:16] CS1_OP1 — RPMC CS1 OP1
  [12:8] CS0_CNT — RPMC CS0 Count
  [7:0] CS0_OP1 — RPMC CS0 OP1
0x330 ACTIVATE 8-bit — eSPI Activate Register
  [0] ACT — 1=Activate. When this bit is '1', the eSPI Logical Device is powered and functional. 0=Deactivate. When this bit is 0, the logical device is powered down and inactive. Except for the eSPI Activate Register itself, clocks to the block are gated and the eSPI Logical Device will permit the main oscillator to be shut down.
0x334 ADDR reset 0x2E0000 — eSPI I/O Base Address Configuration Register
  [31:16] ESP_H_ADDR — These 16 bits are used to match eSPI I/O addresses.
  [0] VALID — 1=The BAR is valid and will participate in eSPI matches. 0=The BAR is ignored.
0x338 ESPI_MEM_ADDR — eSPI Memory Base Address Configuration Register
  fields as ADDR
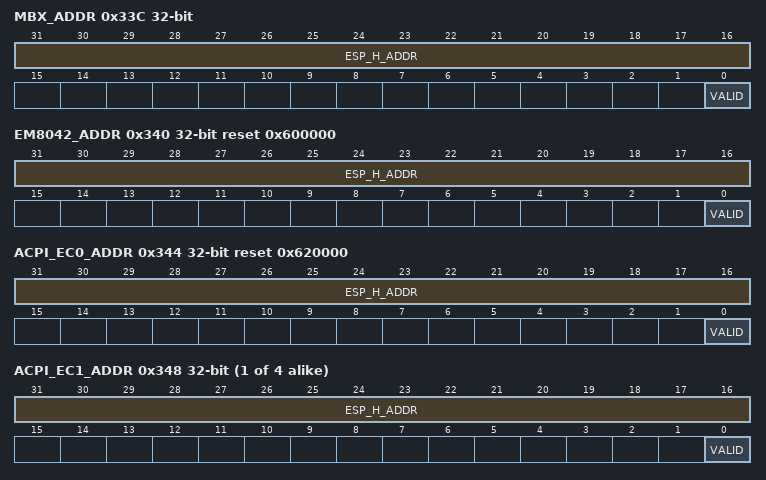
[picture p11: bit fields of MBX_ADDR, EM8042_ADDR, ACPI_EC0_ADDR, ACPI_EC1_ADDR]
0x33C MBX_ADDR — Mailbox Base Address Configuration Register
  fields as ADDR
0x340 EM8042_ADDR reset 0x600000 — 8042 Emulated Keyboard Controller Base Address Configuration Register
  fields as ADDR
0x344 ACPI_EC0_ADDR reset 0x620000 — ACPI EC 0 Base Address Configuration Register
  fields as ADDR
{0x344+4i} ACPI_EC{i}_ADDR (i=1..4) — ACPI EC {i} Base Address Configuration Register
  fields as ADDR
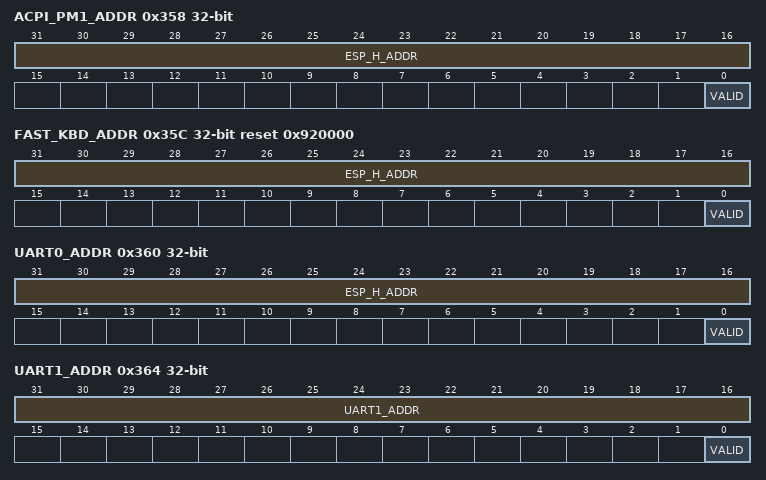
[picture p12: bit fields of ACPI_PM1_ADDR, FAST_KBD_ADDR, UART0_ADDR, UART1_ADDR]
0x358 ACPI_PM1_ADDR — ACPI PM1 Base Address Configuration Register
  fields as ADDR
0x35C FAST_KBD_ADDR reset 0x920000 — I/O Base Address Configuration Register
  fields as ADDR
0x360 UART0_ADDR — UART 0 Base Address Configuration Register
  fields as ADDR
0x364 UART1_ADDR — UART 1 Base Address Configuration Register
  [31:16] UART1_ADDR — These 16 bits are used to match eSPI I/O addresses.
  [0] VALID — 1=The BAR is valid and will participate in eSPI matches. 0=The BAR is ignored.
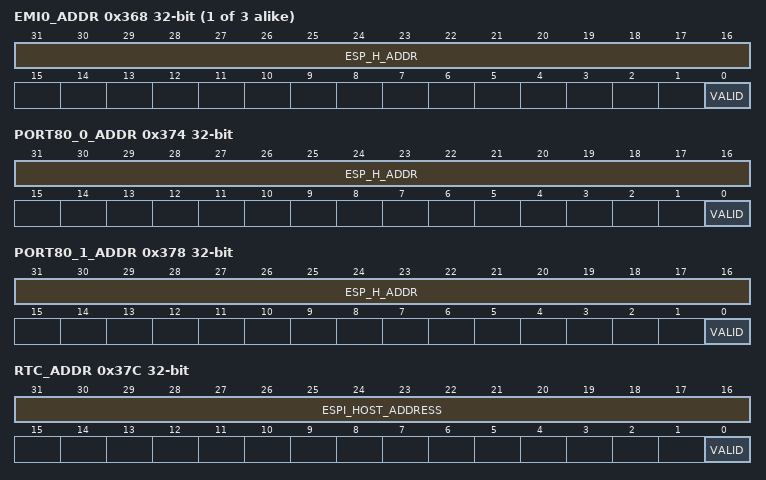
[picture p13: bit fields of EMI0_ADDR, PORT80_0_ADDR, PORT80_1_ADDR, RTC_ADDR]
{0x368+4i} EMI{i}_ADDR (i=0..2) — Embedded Memory Interface (EMI) {i} BAR Config Register
  fields as ADDR
0x374 PORT80_0_ADDR — BIOS Debug Port (Port 80) 0 BAR Config Register
  fields as ADDR
0x378 PORT80_1_ADDR — BIOS Debug Port (Port 80) 1 BAR Config Register
  fields as ADDR
0x37C RTC_ADDR — RTC BAR Config Register
  [31:16] ESPI_HOST_ADDRESS — These 16 bits are used to match eSPI I/O addresses.
  [0] VALID — 1=The BAR is valid and will participate in eSPI matches. 0=The BAR is ignored.
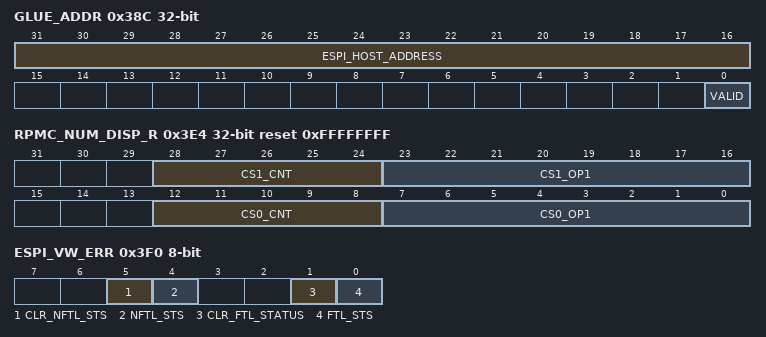
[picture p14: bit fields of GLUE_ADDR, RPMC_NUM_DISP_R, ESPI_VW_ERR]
0x38C GLUE_ADDR — GLUE Base Address Configuration Register
  fields as RTC_ADDR
0x3AC MBX_HOST_SIRQ_IRQ 8-bit reset 0xFF — Mailbox (MBX_Host_SIRQ Interrupt) Selection Register
  [7:0] IRQ — FFh= IRQ generation from this device is disabled. FEh-0=Changes in the value of the signal associated with this register are sent as a Virtual Wire transaction to the Master. The Virtual Wire index is 0 for IRQ values 7Fh to 0h, and the index is 1 for IRQ values FEh to 80h.
0x3AD MBX_HOST_SMI_IRQ 8-bit reset 0xFF — Mailbox (MBX_Host_SMI Interrupt) Selection Register
  fields as MBX_HOST_SIRQ_IRQ
0x3AE KIRQ_8042_IRQ 8-bit reset 0xFF — 8042 (KIRQ Interrupt) Selection Register
  fields as MBX_HOST_SIRQ_IRQ
0x3AF MIRQ_8042_IRQ 8-bit reset 0xFF — 8042 (MIRQ Interrupt) Selection Register
  fields as MBX_HOST_SIRQ_IRQ
{0x3B0+i} ACPI_EC{i}_OBF_IRQ 8-bit reset 0xFF (i=0..4) — ACPI EC {i} (EC_OBF Interrupt) Selection Register
  fields as MBX_HOST_SIRQ_IRQ
0x3B5 UART0_IRQ 8-bit reset 0xFF — UART 0 (UART Interrupt) Selection Register
  fields as MBX_HOST_SIRQ_IRQ
0x3B6 UART1_IRQ 8-bit reset 0xFF — UART 1 (UART Interrupt) Selection Register
  fields as MBX_HOST_SIRQ_IRQ
{0x3B7+2i} EMI{i}_HOST_IRQ 8-bit reset 0xFF (i=0..2) — EMI {i} (Host Event Interrupt) Selection Register
  fields as MBX_HOST_SIRQ_IRQ
{0x3B8+2i} EMI{i}_EC_HOST_IRQ 8-bit reset 0xFF (i=0..2) — EMI {i} (EC-to-Host Interrupt) Selection Register
  fields as MBX_HOST_SIRQ_IRQ
0x3BD RTC_IRQ 8-bit reset 0xFF — RTC (RTC Interrupt) Selection Register
  fields as MBX_HOST_SIRQ_IRQ
0x3BE EC_IRQ 8-bit reset 0xFF — EC (EC_IRQ Interrupt) Selection Register
  fields as MBX_HOST_SIRQ_IRQ
0x3E4 RPMC_NUM_DISP_R ro reset 0xFFFFFFFF — RPMC OP1 Opcode Num Counter Register
  fields as RPMC_NUM_DISP_RW
0x3F0 ESPI_VW_ERR 8-bit — eSPI Virtual Wire Errors Register
  [5] CLR_NFTL_STS — When this field is written with a 1 the Virtual Wire ERROR_NON_- FATAL (bit 2 in Slave-to-Master Virtual Wire Index 5h) is cleared to 0. Because clearing the status bit changes its state, a Virtual Wire packet reporting the new state will be sent to the Master. Writes of 0 to this bit have no effect. Reads of this bit always return '0'.
  [4] NFTL_STS — This bit is a Master-readable copy of the Virtual Wire ERROR_NON_FATAL (bit 2 in Slave-to-Master Virtual Wire Index 5h).
  [1] CLR_FTL_STATUS — When this field is written with a 1 the Virtual Wire ERROR_FATAL (bit 1 in Slave-to-Master Virtual Wire Index 5h) is cleared to 0. Because clearing the status bit changes its state, a Virtual Wire packet reporting the new state will be sent to the Master. Writes of 0 to this bit have no effect. Reads of this bit always return '0'.
  [0] FTL_STS — This bit is a Master-readable copy of the Virtual Wire ERROR_FATAL (bit 1 in Slave-to-Master Virtual Wire Index 5h).
